# ATSAME53J18A register map
Vendor: Microchip Technology Inc.; Series: SAME53; File version: A
CPU: CM4 r0p1, little endian, MPU, FPU, 3 interrupt priority bits, 137 interrupts
Registers are 32-bit, read-write, reset 0x0 unless marked. A register's access mark holds for its fields unless they carry their own. Offsets are from the block's base; [hi:lo] are bit positions; {n}, {i} and the like mark numbered series; 'fields as' and 'values as' point back to an identical list.

## CCL — Configurable Custom Logic
Base 0x42003800; register names take the prefix CCL_
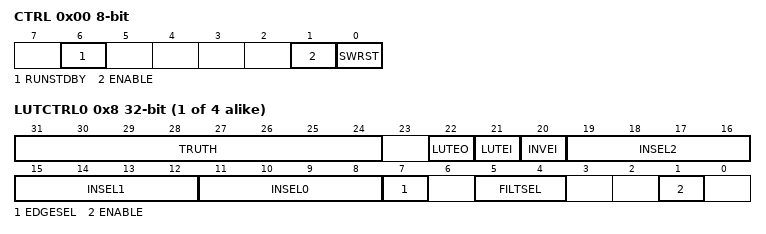
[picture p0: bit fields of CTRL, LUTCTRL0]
0x00 CTRL 8-bit — Control
  [6] RUNSTDBY — Run in Standby
  [1] ENABLE
  [0] SWRST wo — Software Reset
{0x4+i} SEQCTRL{i} (i=0..1) 8-bit — SEQ Control x
  [3:0] SEQSEL — Sequential Selection
    0=DISABLE (Sequential logic is disabled); 1=DFF (D flip flop); 2=JK (JK flip flop); 3=LATCH (D latch); 4=RS (RS latch)
{0x8+4i} LUTCTRL{i} (i=0..3) — LUT Control x
  [31:24] TRUTH — Truth Value
  [22] LUTEO — LUT Event Output Enable
  [21] LUTEI — LUT Event Input Enable
  [20] INVEI — Inverted Event Input Enable
  [19:16] INSEL2 — Input Selection 2
    0=MASK (Masked input); 1=FEEDBACK (Feedback input source); 2=LINK (Linked LUT input source); 3=EVENT (Event input source); 4=IO (I/O pin input source); 5=AC (AC input source); 6=TC (TC input source); 7=ALTTC (Alternate TC input source); 8=TCC (TCC input source); 9=SERCOM (SERCOM input source)
  [15:12] INSEL1 — Input Selection 1
    values as INSEL2
  [11:8] INSEL0 — Input Selection 0
    values as INSEL2
  [7] EDGESEL — Edge Selection
  [5:4] FILTSEL — Filter Selection
    0=DISABLE (Filter disabled); 1=SYNCH (Synchronizer enabled); 2=FILTER (Filter enabled)
  [1] ENABLE — LUT Enable

## CMCC — Cortex M Cache Controller
Base 0x41006000; register names take the prefix CMCC_
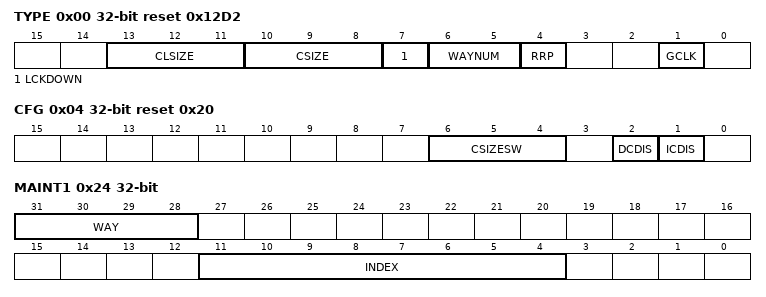
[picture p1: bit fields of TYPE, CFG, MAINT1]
0x00 TYPE ro reset 0x12D2 — Cache Type Register
  [13:11] CLSIZE — Cache Line Size
    0=CLSIZE_4B (Cache Line Size is 4 bytes); 1=CLSIZE_8B (Cache Line Size is 8 bytes); 2=CLSIZE_16B (Cache Line Size is 16 bytes); 3=CLSIZE_32B (Cache Line Size is 32 bytes); 4=CLSIZE_64B (Cache Line Size is 64 bytes); 5=CLSIZE_128B (Cache Line Size is 128 bytes)
  [10:8] CSIZE — Cache Size
    0=CSIZE_1KB (Cache Size is 1 KB); 1=CSIZE_2KB (Cache Size is 2 KB); 2=CSIZE_4KB (Cache Size is 4 KB); 3=CSIZE_8KB (Cache Size is 8 KB); 4=CSIZE_16KB (Cache Size is 16 KB); 5=CSIZE_32KB (Cache Size is 32 KB); 6=CSIZE_64KB (Cache Size is 64 KB)
  [7] LCKDOWN — Lock Down supported
  [6:5] WAYNUM — Number of Way
    0=DMAPPED (Direct Mapped Cache); 1=ARCH2WAY (2-WAY set associative); 2=ARCH4WAY (4-WAY set associative)
  [4] RRP — Round Robin Policy supported
  [1] GCLK — dynamic Clock Gating supported
0x04 CFG reset 0x20 — Cache Configuration Register
  [6:4] CSIZESW — Cache size configured by software
    0=CONF_CSIZE_1KB (the Cache Size is configured to 1KB); 1=CONF_CSIZE_2KB (the Cache Size is configured to 2KB); 2=CONF_CSIZE_4KB (the Cache Size is configured to 4KB); 3=CONF_CSIZE_8KB (the Cache Size is configured to 8KB); 4=CONF_CSIZE_16KB (the Cache Size is configured to 16KB); 5=CONF_CSIZE_32KB (the Cache Size is configured to 32KB); 6=CONF_CSIZE_64KB (the Cache Size is configured to 64KB)
  [2] DCDIS — Data Cache Disable
  [1] ICDIS — Instruction Cache Disable
0x08 CTRL wo — Cache Control Register
  [0] CEN — Cache Controller Enable
0x0C SR ro — Cache Status Register
  [0] CSTS — Cache Controller Status
0x10 LCKWAY — Cache Lock per Way Register
  [3:0] LCKWAY — Lockdown way Register
0x20 MAINT0 wo — Cache Maintenance Register 0
  [0] INVALL — Cache Controller invalidate All
0x24 MAINT1 wo — Cache Maintenance Register 1
  [31:28] WAY — Invalidate Way
    {v}=Way {v} is selection for index invalidation (v=0..3)
  [11:4] INDEX — Invalidate Index
0x28 MCFG — Cache Monitor Configuration Register
  [1:0] MODE — Cache Controller Monitor Counter Mode
    0=CYCLE_COUNT (cycle counter); 1=IHIT_COUNT (instruction hit counter); 2=DHIT_COUNT (data hit counter)
0x2C MEN — Cache Monitor Enable Register
  [0] MENABLE — Cache Controller Monitor Enable
0x30 MCTRL wo — Cache Monitor Control Register
  [0] SWRST — Cache Controller Software Reset
0x34 MSR ro — Cache Monitor Status Register
  [31:0] EVENT_CNT — Monitor Event Counter
